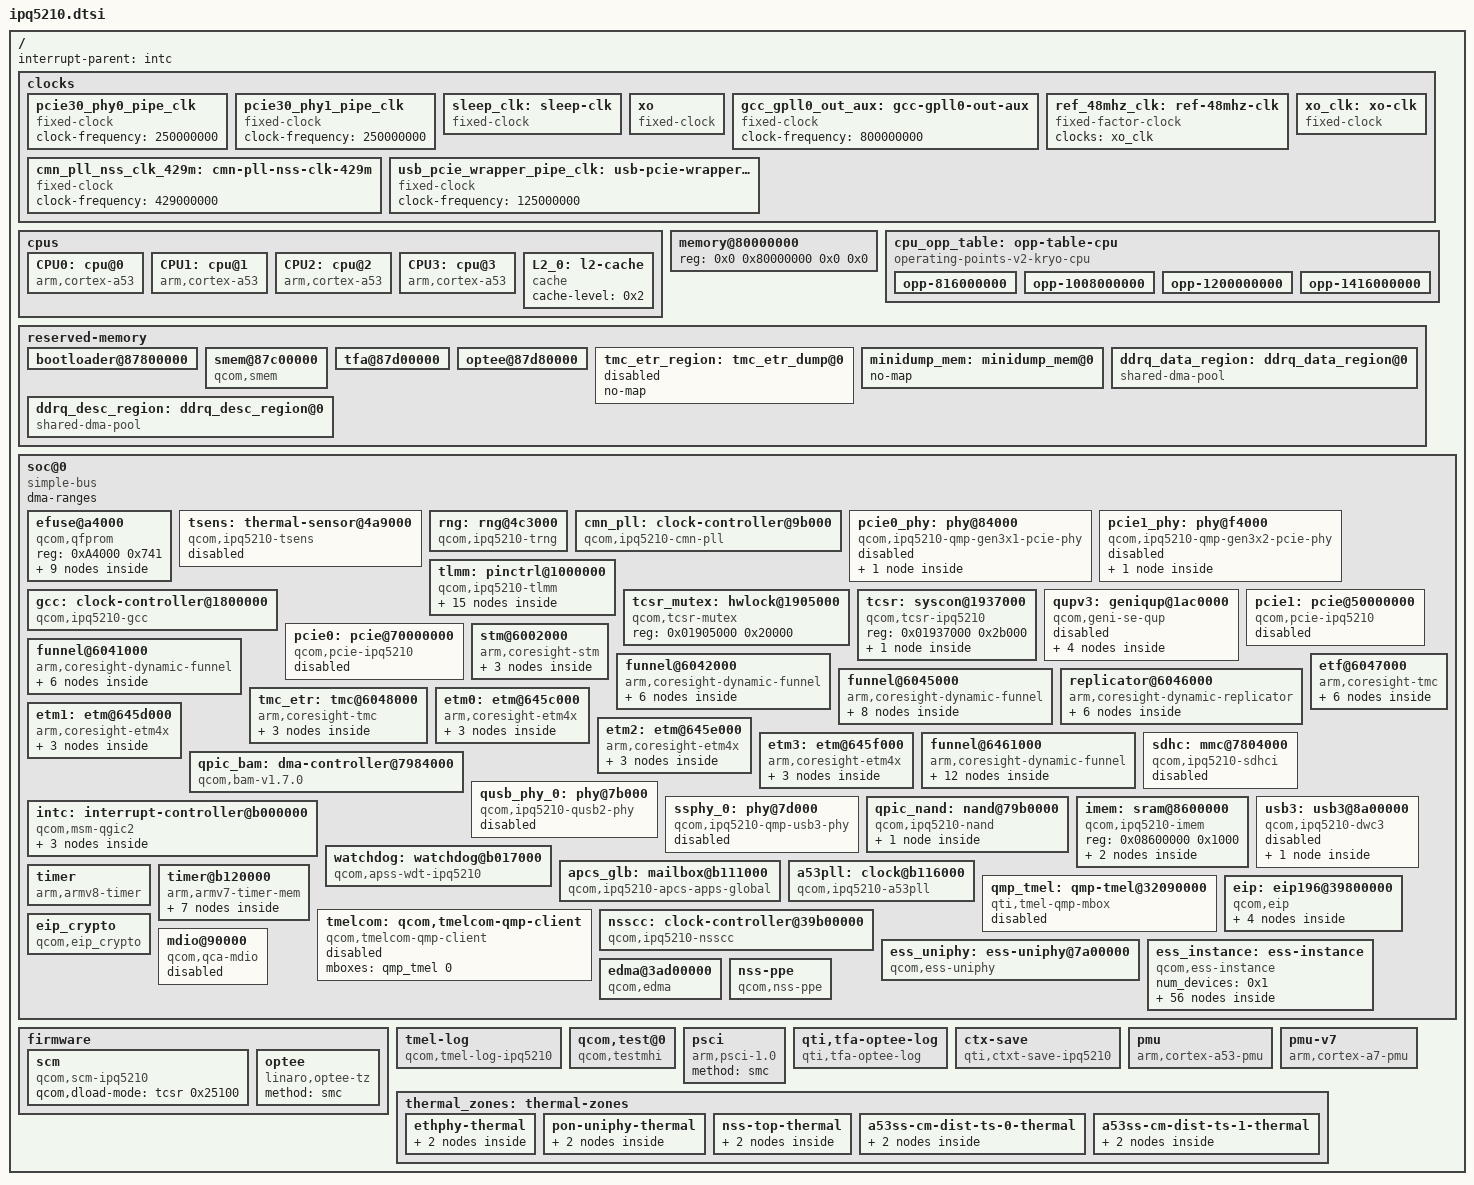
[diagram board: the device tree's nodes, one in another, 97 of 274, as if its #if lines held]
// SPDX-License-Identifier: (GPL-2.0+ OR BSD-3-Clause)
/*
 * IPQ5210 device tree source
 *
 * Copyright (c) 2020-2021 The Linux Foundation. All rights reserved.
 * Copyright (c) Qualcomm Technologies, Inc. and/or its subsidiaries.
 */

#include <dt-bindings/clock/qcom,apss-ipq.h>
#include <dt-bindings/clock/qcom,ipq5210-cmn-pll.h>
#include <dt-bindings/clock/qcom,ipq5210-gcc.h>
#include <dt-bindings/clock/qcom,ipq5210-nsscc.h>
#include <dt-bindings/reset/qcom,ipq5210-gcc.h>
#include <dt-bindings/reset/qcom,ipq5210-nsscc.h>
#include <dt-bindings/interrupt-controller/arm-gic.h>
#include <dt-bindings/gpio/gpio.h>

/ {
	#address-cells = <2>;
	#size-cells = <2>;
	interrupt-parent = <&intc>;

	clocks {
		pcie30_phy0_pipe_clk: pcie30_phy0_pipe_clk {
			compatible = "fixed-clock";
			clock-frequency = <250000000>;
			#clock-cells = <0>;
		};

		pcie30_phy1_pipe_clk: pcie30_phy1_pipe_clk {
			compatible = "fixed-clock";
			clock-frequency = <250000000>;
			#clock-cells = <0>;
		};

		sleep_clk: sleep-clk {
			compatible = "fixed-clock";
			#clock-cells = <0>;
		};

		xo: xo {
			compatible = "fixed-clock";
			#clock-cells = <0>;
		};

		gcc_gpll0_out_aux: gcc-gpll0-out-aux {
			compatible = "fixed-clock";
			clock-frequency = <800000000>;
			#clock-cells = <0>;
		};

		ref_48mhz_clk: ref-48mhz-clk {
			compatible = "fixed-factor-clock";
			clocks = <&xo_clk>;
			#clock-cells = <0>;
		};

		xo_clk: xo-clk {
			compatible = "fixed-clock";
			#clock-cells = <0>;
		};

		cmn_pll_nss_clk_429m: cmn-pll-nss-clk-429m {
			compatible = "fixed-clock";
			clock-frequency = <429000000>;
			#clock-cells = <0>;
		};

		usb_pcie_wrapper_pipe_clk: usb-pcie-wrapper-pipe-clk {
			compatible = "fixed-clock";
			clock-frequency = <125000000>;
			#clock-cells = <0>;
		};
	};

	cpus: cpus {
		#address-cells = <1>;
		#size-cells = <0>;

		CPU0: cpu@0 {
			device_type = "cpu";
			compatible = "arm,cortex-a53";
			reg = <0x0>;
			enable-method = "psci";
			next-level-cache = <&L2_0>;
			clocks = <&apcs_glb APCS_ALIAS0_CORE_CLK>;
			clock-names = "cpu";
			operating-points-v2 = <&cpu_opp_table>;
		};

		CPU1: cpu@1 {
			device_type = "cpu";
			compatible = "arm,cortex-a53";
			enable-method = "psci";
			reg = <0x1>;
			next-level-cache = <&L2_0>;
			clocks = <&apcs_glb APCS_ALIAS0_CORE_CLK>;
			clock-names = "cpu";
			operating-points-v2 = <&cpu_opp_table>;
		};

		CPU2: cpu@2 {
			device_type = "cpu";
			compatible = "arm,cortex-a53";
			enable-method = "psci";
			reg = <0x2>;
			next-level-cache = <&L2_0>;
			clocks = <&apcs_glb APCS_ALIAS0_CORE_CLK>;
			clock-names = "cpu";
			operating-points-v2 = <&cpu_opp_table>;
		};

		CPU3: cpu@3 {
			device_type = "cpu";
			compatible = "arm,cortex-a53";
			enable-method = "psci";
			reg = <0x3>;
			next-level-cache = <&L2_0>;
			clocks = <&apcs_glb APCS_ALIAS0_CORE_CLK>;
			clock-names = "cpu";
			operating-points-v2 = <&cpu_opp_table>;
		};

		L2_0: l2-cache {
			compatible = "cache";
			cache-level = <0x2>;
		};
	};

	memory@80000000 {
		device_type = "memory";
		/* We expect the bootloader to fill in the size */
		reg = <0x0 0x80000000 0x0 0x0 >;
	};

	cpu_opp_table: opp-table-cpu {
		compatible = "operating-points-v2-kryo-cpu";
		opp-shared;
		nvmem-cells = <&apss_cpu_freq>;
		nvmem-cell-names = "cpu_freq";

		/* Listed all supported CPU frequencies and opp-supported-hw
		 * values to select CPU frequencies based on the PLL LValue.
		 * ------------------------------------------------------------
		 * Frequency     1.2GHz   1.4GHz	opp-supported-hw
		 * ------------------------------------------------------------
		 * 816000000       1	      1			0x3
		 * 1008000000	   1	      1			0x3
		 * 1200000000      1	      1			0x3
		 * 1416000000      0	      1			0x1
		 * -----------------------------------------------------------*/

		opp-816000000 {
			opp-hz = /bits/ 64 <816000000>;
			opp-supported-hw = <0x3>;
			opp-microvolt = <850000>;
			clock-latency-ns = <200000>;
		};

		opp-1008000000 {
			opp-hz = /bits/ 64 <1008000000>;
			opp-supported-hw = <0x3>;
			opp-microvolt = <850000>;
			clock-latency-ns = <200000>;
		};

		opp-1200000000 {
			opp-hz = /bits/ 64 <1200000000>;
			opp-supported-hw = <0x3>;
			opp-microvolt = <850000>;
			clock-latency-ns = <200000>;
		};

		opp-1416000000 {
			opp-hz = /bits/ 64 <1416000000>;
			opp-supported-hw = <0x1>;
			opp-microvolt = <1000000>;
			clock-latency-ns = <200000>;
		};
	};

	reserved-memory {
		#address-cells = <2>;
		#size-cells = <2>;
		ranges;

		bootloader@87800000 {
			reg = <0x0 0x87800000 0x0 0x400000>;
			no-map;
		};

		smem@87c00000 {
			compatible = "qcom,smem";
			reg = <0x0 0x87c00000 0x0 0x40000>;
			no-map;

			hwlocks = <&tcsr_mutex 3>;
		};

		tfa@87d00000 {
			reg = <0x0 0x87d00000 0x0 0x80000>;
			no-map;
		};

		optee@87d80000 {
#ifdef __IPQ_MEM_PROFILE_256_MB__
			reg = <0x0 0x87d80000 0x0 0x80000>;
#else
			reg = <0x0 0x87d80000 0x0 0x280000>;
#endif
			no-map;
		};

		tmc_etr_region: tmc_etr_dump@0 {
			no-map;
			status = "disabled";
		};

		minidump_mem: minidump_mem@0 {
			no-map;
		};

		/*
		 * DDRQ data region details
		 */
		ddrq_data_region: ddrq_data_region@0 {
			compatible = "shared-dma-pool";
			no-map;
			size = <0x0 0x00800000>;	/* 8MB */
		};

		/*
		 * DDRQ descriptor memory details
		 */
		ddrq_desc_region: ddrq_desc_region@0 {
			compatible = "shared-dma-pool";
			no-map;
			size = <0x0 0x00080000>;	/* 512KB */
		};
	};

	soc@0 {
		compatible = "simple-bus";
		#address-cells = <1>;
		#size-cells = <1>;
		ranges = <0 0 0 0xffffffff>;
		dma-ranges;

		efuse@a4000 {
			compatible = "qcom,qfprom";
			reg = <0xA4000 0x741>;
			#address-cells = <1>;
			#size-cells = <1>;

			apss_cpu_freq: apss_cpu_freq@28 {
				reg = <0x28 0x1>;
				bits = <0 8>;
			};

			s11: s11@3dd {
				reg = <0x3dd 0x1>;
				bits = <4 4>;
			};

			s12: s12@3de {
				reg = <0x3de 0x1>;
				bits = <0 4>;
			};

			s13: s13@3de {
				reg = <0x3de 0x1>;
				bits = <4 4>;
			};

			s14: s14@3e5 {
				reg = <0x3e5 0x2>;
				bits = <7 4>;
			};

			s15: s15@3e6 {
				reg = <0x3e6 0x1>;
				bits = <3 4>;
			};

			tsens_mode: mode@419 {
				reg = <0x419 0x1>;
				bits = <0 3>;
			};

			tsens_base0: base0@419 {
				reg = <0x419 0x2>;
				bits = <3 10>;
			};

			tsens_base1: base1@41a {
				reg = <0x41a 0x2>;
				bits = <5 10>;
			};
		};

		tsens: thermal-sensor@4a9000 {
			compatible = "qcom,ipq5210-tsens";
			reg = <0x4a9000 0x1000>,
			      <0x4a8000 0x1000>;
			nvmem-cells = <&tsens_mode>, <&tsens_base0>, <&tsens_base1>,
				      <&s11>, <&s12>, <&s13>, <&s14>, <&s15>;
			nvmem-cell-names = "mode", "base0", "base1", "s11",
					   "s12", "s13", "s14", "s15";
			interrupts = <GIC_SPI 52 IRQ_TYPE_EDGE_RISING>;
			interrupt-names = "combined";
			#thermal-sensor-cells = <1>;
			status = "disabled";
		};

		rng: rng@4c3000 {
			compatible = "qcom,ipq5210-trng", "qcom,trng";
			reg = <0x004c3000 0x1000>;
			clocks = <&gcc GCC_QRNG_AHB_CLK>;
			clock-names = "core";
		};

		cmn_pll: clock-controller@9b000 {
			compatible = "qcom,ipq5210-cmn-pll";
			reg = <0x0009b000 0x800>;
			clocks = <&ref_48mhz_clk>,
				 <&gcc GCC_CMN_12GPLL_AHB_CLK>,
				 <&gcc GCC_CMN_12GPLL_SYS_CLK>;
			clock-names = "ref", "ahb", "sys";
			#clock-cells = <1>;
			assigned-clocks = <&cmn_pll IPQ5210_CMN_PLL_CLK>;
			assigned-clock-rates-u64 = /bits/ 64 <12000000000>;
		};

		pcie0_phy: phy@84000 {
			compatible = "qcom,ipq5210-qmp-gen3x1-pcie-phy";
			reg = <0x00084000 0x1bc>; /* Serdes PLL */
			#address-cells = <1>;
			#size-cells = <1>;
			ranges;

			clocks = <&gcc GCC_PCIE0_AUX_CLK>,
				 <&gcc GCC_PCIE0_AHB_CLK>,
				 <&gcc GCC_SNOC_PCIE0_AXI_M_CLK>,
				 <&gcc GCC_CNOC_PCIE0_1LANE_S_CLK>;
			clock-names = "aux", "cfg_ahb", "snoc_lane", "anoc_lane";

			assigned-clocks = <&gcc GCC_PCIE0_AUX_CLK>,
					  <&gcc GCC_PCIE0_AHB_CLK>,
					  <&gcc GCC_SNOC_PCIE0_AXI_M_CLK>,
					  <&gcc GCC_CNOC_PCIE0_1LANE_S_CLK>;
			assigned-clock-rates = <20000000>,
					       <100000000>,
					       <200000000>,
					       <240000000>;

			resets = <&gcc GCC_PCIE0_PHY_BCR>,
				 <&gcc GCC_PCIE0PHY_PHY_BCR>;
			reset-names = "phy", "common";

			status = "disabled";

			pcie0_lanes: phy@84200 {
				reg = <0x00084200 0x16c>, /* Serdes Tx0 */
				      <0x00084400 0x200>, /* Serdes Rx0 */
				      <0x00084800 0x1f0>, /* PCS: Lane0, COM, PCIE */
				      <0x00084c00 0x0f4>; /* pcs_misc */

				#phy-cells = <0>;

				clocks = <&gcc GCC_PCIE0_PIPE_CLK>;
				clock-names = "pipe0";
				clock-output-names = "gcc_pcie0_pipe_clk_src";
				#clock-cells = <0>;
			};
		};

		pcie1_phy: phy@f4000 {
			compatible = "qcom,ipq5210-qmp-gen3x2-pcie-phy",
				     "qcom,ipq9574-qmp-gen3x2-pcie-phy";
			reg = <0x000f4000 0x1bc>; /* Serdes PLL */
			#address-cells = <1>;
			#size-cells = <1>;
			ranges;

			clocks = <&gcc GCC_PCIE1_AUX_CLK>,
				 <&gcc GCC_PCIE1_AHB_CLK>,
				 <&gcc GCC_SNOC_PCIE1_AXI_M_CLK>,
				 <&gcc GCC_CNOC_PCIE1_2LANE_S_CLK>;
			clock-names = "aux", "cfg_ahb", "snoc_lane", "anoc_lane";

			assigned-clocks = <&gcc GCC_PCIE1_AUX_CLK>,
					  <&gcc GCC_PCIE1_AHB_CLK>,
					  <&gcc GCC_SNOC_PCIE1_AXI_M_CLK>,
					  <&gcc GCC_CNOC_PCIE1_2LANE_S_CLK>;
			assigned-clock-rates = <20000000>,
					       <100000000>,
					       <266666666>,
					       <240000000>;

			resets = <&gcc GCC_PCIE1_PHY_BCR>,
				 <&gcc GCC_PCIE1PHY_PHY_BCR>;
			reset-names = "phy", "common";

			status = "disabled";

			pcie1_lanes: phy@f4200 {
				reg = <0x000f4200 0x16c>, /* Serdes Tx0 */
				      <0x000f4400 0x200>, /* Serdes Rx0 */
				      <0x000f5000 0x1f0>, /* PCS: Lane0, COM, PCIE */
				      <0x000f4600 0x16c>, /* Serdes Tx1 */
				      <0x000f4800 0x200>, /* Serdes Rx1 */
				      <0x000f5400 0x0f8>; /* pcs_misc */

				#phy-cells = <0>;

				clocks = <&gcc GCC_PCIE1_PIPE_CLK>;
				clock-names = "pipe0";
				clock-output-names = "gcc_pcie1_pipe_clk_src";
				#clock-cells = <0>;
			};
		};

		tlmm: pinctrl@1000000 {
			compatible = "qcom,ipq5210-tlmm";
			reg = <0x1000000 0x300000>;
			interrupts = <GIC_SPI 31 IRQ_TYPE_LEVEL_HIGH>;
			gpio-controller;
			#gpio-cells = <2>;
			gpio-ranges = <&tlmm 0 0 54>;
			interrupt-controller;
			#interrupt-cells = <2>;

			mdio_pins: mdio-state {
				mux_0 {
					pins = "gpio26";
					function = "mdc_mst";
					drive-strength = <6>;
					bias-pull-down;
				};

				mux_1 {
					pins = "gpio27";
					function = "mdio_mst";
					drive-strength = <6>;
					bias-pull-down;
				};
			};

                        pon_cmn_pins: pon-cmn-pins {

				pon_active_led {
					pins = "gpio11";
					function = "pon_active_led";
					drive-strength = <6>;
					bias-pull-down;
				};

				pon_tx_pwr_on {
					pins = "gpio15";
					function = "pon_tx";
					drive-strength = <6>;
					bias-pull-down;
				};

				pon_rx_pwr_on {
					pins = "gpio48";
					function = "pon_rx";
					drive-strength = <6>;
					bias-pull-down;
				};
			};

			xgspon_pins: xgspon-pins {

				pon_tx_burst {
					pins = "gpio14";
					function = "pon_tx_burst";
					drive-strength = <6>;
					bias-disable;
				};

				pon_tx_fault {
					pins = "gpio17";
					function = "pon_tx_fault";
					drive-strength = <6>;
					bias-pull-down;
				};

				pon_tx_sd {
					pins = "gpio16";
					function = "pon_tx_sd";
					drive-strength = <6>;
					bias-pull-down;
				};

				pon_rx_los {
					pins = "gpio10";
					function = "pon_rx_los";
					drive-strength = <6>;
					bias-pull-up;
				};

				pon_tx_dis {
					pins = "gpio12";
					function = "pon_tx_dis";
					drive-strength = <6>;
					bias-pull-down;
				};
			};

			pps_state: pps-state {
				pps-pins {
					pins = "gpio18";
					function = "pps";
					drive-strength = <8>;
					bias-pull-down;
				};
			};
		};

		gcc: clock-controller@1800000 {
			compatible = "qcom,ipq5210-gcc";
			reg = <0x01800000 0x40000>;
			clocks = <&xo>,
				 <&sleep_clk>,
				 <&pcie30_phy0_pipe_clk>,
				 <&pcie30_phy1_pipe_clk>,
				 <&usb_pcie_wrapper_pipe_clk>,
				 <&cmn_pll_nss_clk_429m>;
			#clock-cells = <1>;
			#reset-cells = <1>;
			#power-domain-cells = <1>;
		};

		tcsr_mutex: hwlock@1905000 {
			compatible = "qcom,tcsr-mutex";
			reg = <0x01905000 0x20000>;
			#hwlock-cells = <1>;
		};

		tcsr: syscon@1937000 {
			compatible = "qcom,tcsr-ipq5210", "syscon", "simple-mfd";
			reg = <0x01937000 0x2b000>;
			#address-cells = <1>;
			#size-cells = <1>;
			ranges = <0x0 0x01937000 0x2b000>;

			pwm: pwm@a010 {
				compatible = "qcom,ipq9574-pwm";
				reg = <0xa010 0x20>;
				clocks = <&gcc GCC_ADSS_PWM_CLK>;
				assigned-clocks = <&gcc GCC_ADSS_PWM_CLK>;
				assigned-clock-rates = <100000000>;
				#pwm-cells = <2>;
				status = "disabled";
			};
		};

		qupv3: geniqup@1ac0000 {
			compatible = "qcom,geni-se-qup";
			reg = <0x01ac0000 0x2000>;
			clocks = <&gcc GCC_QUPV3_AHB_MST_CLK>,
				 <&gcc GCC_QUPV3_AHB_SLV_CLK>;
			clock-names = "m-ahb", "s-ahb";
			ranges;
			#address-cells = <1>;
			#size-cells = <1>;

			status = "disabled";

			spi0: spi@1a80000 {
				compatible = "qcom,geni-spi";
				reg = <0x1a80000 0x4000>;
				clocks = <&gcc GCC_QUPV3_WRAP_SE0_CLK>;
				clock-names = "se";
				interrupts = <GIC_SPI 138 IRQ_TYPE_LEVEL_HIGH>;
				assigned-clocks = <&gcc GCC_QUPV3_WRAP_SE0_CLK>;
				assigned-clock-rates = <50000000>;
				status = "disabled";
			};

			uart1: serial@1a84000 {
				compatible = "qcom,geni-debug-uart";
				reg = <0x1a84000 0x4000>;
				clocks = <&gcc GCC_QUPV3_WRAP_SE1_CLK>;
				clock-names = "se";
				interrupts = <GIC_SPI 139 IRQ_TYPE_LEVEL_HIGH>;
				status = "disabled";
			};

			i2c0: i2c@1a88000 {
				compatible = "qcom,geni-i2c";
				reg = <0x1a88000 0x4000>;
				clocks = <&gcc GCC_QUPV3_WRAP_SE2_CLK>;
				clock-names = "se";
				clock-frequency = <400000>;
				interrupts = <GIC_SPI 140 IRQ_TYPE_LEVEL_HIGH>;
				assigned-clocks = <&gcc GCC_QUPV3_WRAP_SE2_CLK>;
				assigned-clock-rates = <32000000>;
				status = "disabled";
			};

			i2c1: i2c@1a8c000 {
				compatible = "qcom,geni-i2c";
				reg = <0x1a8c000 0x4000>;
				clocks = <&gcc GCC_QUPV3_WRAP_SE3_CLK>;
				clock-names = "se";
				clock-frequency = <400000>;
				interrupts = <GIC_SPI 141 IRQ_TYPE_LEVEL_HIGH>;
				assigned-clocks = <&gcc GCC_QUPV3_WRAP_SE3_CLK>;
				assigned-clock-rates = <32000000>;
				status = "disabled";
			};
		};

		pcie1: pcie@50000000 {
			compatible = "qcom,pcie-ipq5210";
			reg =  <0x50000000 0xf1d>,
			       <0x50000f20 0xa8>,
			       <0x50001000 0x1000>,
			       <0xf0000 0x3000>,
			       <0x50100000 0x1000>;
			reg-names = "dbi", "elbi", "atu", "parf", "config";
			device_type = "pci";
			linux,pci-domain = <1>;
			bus-range = <0x00 0xff>;
			num-lanes = <2>;
			#address-cells = <3>;
			#size-cells = <2>;
			qcom,aspm-enabled;
			axi-halt-val = <0x1e>; /* increase halt window size to 1GB */

			ranges = <0x81000000 0 0x50200000 0x50200000 0 0x00100000>,   /* downstream I/O */
				 <0x82000000 0 0x50300000 0x50300000 0 0x0fd00000>; /* non-prefetchable memory */

			#interrupt-cells = <1>;
			interrupt-map-mask = <0 0 0 0x7>;
			interrupt-map = <0 0 0 1 &intc 0 200 IRQ_TYPE_LEVEL_HIGH>, /* int_a */
					<0 0 0 2 &intc 0 201 IRQ_TYPE_LEVEL_HIGH>, /* int_b */
					<0 0 0 3 &intc 0 202 IRQ_TYPE_LEVEL_HIGH>, /* int_c */
					<0 0 0 4 &intc 0 203 IRQ_TYPE_LEVEL_HIGH>; /* int_d */

			interrupts = <GIC_SPI 199 IRQ_TYPE_LEVEL_HIGH>;
			interrupt-names = "global_irq";

			clocks = <&gcc GCC_PCIE1_AXI_M_CLK>,
				 <&gcc GCC_PCIE1_AXI_S_CLK>,
				 <&gcc GCC_PCIE1_AHB_CLK>,
				 <&gcc GCC_PCIE1_AUX_CLK>,
				 <&gcc GCC_PCIE1_AXI_S_BRIDGE_CLK>,
				 <&gcc GCC_PCIE1_RCHNG_CLK>;

			clock-names = "axi_m",
				      "axi_s",
				      "ahb",
				      "aux",
				      "axi_bridge",
				      "rchng";

			assigned-clocks = <&gcc GCC_PCIE1_AHB_CLK>,
					<&gcc GCC_PCIE1_AUX_CLK>,
					<&gcc GCC_PCIE1_AXI_M_CLK>,
					<&gcc GCC_PCIE1_AXI_S_BRIDGE_CLK>,
					<&gcc GCC_PCIE1_AXI_S_CLK>,
					<&gcc GCC_PCIE1_RCHNG_CLK>;

			assigned-clock-rates = <100000000>,
						<20000000>,
						<266666666>,
						<240000000>,
						<240000000>,
						<100000000>;

			resets = <&gcc GCC_PCIE1_PIPE_ARES>,
				 <&gcc GCC_PCIE1_CORE_STICKY_RESET>,
				 <&gcc GCC_PCIE1_AXI_M_ARES>,
				 <&gcc GCC_PCIE1_AXI_S_ARES>,
				 <&gcc GCC_PCIE1_AXI_M_STICKY_RESET>,
				 <&gcc GCC_PCIE1_AXI_S_STICKY_RESET>,
				 <&gcc GCC_PCIE1_AHB_ARES>,
				 <&gcc GCC_PCIE1_AUX_ARES>;

			reset-names = "pipe",
				      "sticky",
				      "axi_m",
				      "axi_s",
				      "axi_m_sticky",
				      "axi_s_sticky",
				      "ahb",
				      "aux";

			msi-parent = <&v2m0>;

			phys = <&pcie1_lanes>;
			phy-names = "pciephy";

			status = "disabled";
		};

		pcie0: pcie@70000000 {
			compatible = "qcom,pcie-ipq5210";
			reg =  <0x70000000 0xf1d>,
			       <0x70000f20 0xa8>,
			       <0x70001000 0x1000>,
			       <0x80000 0x3000>,
			       <0x70100000 0x1000>;
			reg-names = "dbi", "elbi", "atu", "parf", "config";
			device_type = "pci";
			linux,pci-domain = <0>;
			bus-range = <0x00 0xff>;
			num-lanes = <1>;
			#address-cells = <3>;
			#size-cells = <2>;
			qcom,aspm-enabled;
			axi-halt-val = <0x1e>; /* increase halt window size to 1GB */

			ranges = <0x81000000 0 0x70200000 0x70200000 0 0x00100000>,   /* downstream I/O */
				 <0x82000000 0 0x70300000 0x70300000 0 0x0fd00000>; /* non-prefetchable memory */

			#interrupt-cells = <1>;
			interrupt-map-mask = <0 0 0 0x7>;
			interrupt-map = <0 0 0 1 &intc 0 185 IRQ_TYPE_LEVEL_HIGH>, /* int_a */
					<0 0 0 2 &intc 0 186 IRQ_TYPE_LEVEL_HIGH>, /* int_b */
					<0 0 0 3 &intc 0 187 IRQ_TYPE_LEVEL_HIGH>, /* int_c */
					<0 0 0 4 &intc 0 188 IRQ_TYPE_LEVEL_HIGH>; /* int_d */

			interrupts = <GIC_SPI 184 IRQ_TYPE_LEVEL_HIGH>;
			interrupt-names = "global_irq";

			clocks = <&gcc GCC_PCIE0_AXI_M_CLK>,
				 <&gcc GCC_PCIE0_AXI_S_CLK>,
				 <&gcc GCC_PCIE0_AHB_CLK>,
				 <&gcc GCC_PCIE0_AUX_CLK>,
				 <&gcc GCC_PCIE0_AXI_S_BRIDGE_CLK>,
				 <&gcc GCC_PCIE0_RCHNG_CLK>;

			clock-names = "axi_m",
				      "axi_s",
				      "ahb",
				      "aux",
				      "axi_bridge",
				      "rchng";

			assigned-clocks = <&gcc GCC_PCIE0_AHB_CLK>,
					<&gcc GCC_PCIE0_AUX_CLK>,
					<&gcc GCC_PCIE0_AXI_M_CLK>,
					<&gcc GCC_PCIE0_AXI_S_BRIDGE_CLK>,
					<&gcc GCC_PCIE0_AXI_S_CLK>,
					<&gcc GCC_PCIE0_RCHNG_CLK>;

			assigned-clock-rates = <100000000>,
						<20000000>,
						<240000000>,
						<240000000>,
						<240000000>,
						<100000000>;

			resets = <&gcc GCC_PCIE0_PIPE_ARES>,
				 <&gcc GCC_PCIE0_CORE_STICKY_RESET>,
				 <&gcc GCC_PCIE0_AXI_M_ARES>,
				 <&gcc GCC_PCIE0_AXI_S_ARES>,
				 <&gcc GCC_PCIE0_AXI_M_STICKY_RESET>,
				 <&gcc GCC_PCIE0_AXI_S_STICKY_RESET>,
				 <&gcc GCC_PCIE0_AHB_ARES>,
				 <&gcc GCC_PCIE0_AUX_ARES>;

			reset-names = "pipe",
				      "sticky",
				      "axi_m",
				      "axi_s",
				      "axi_m_sticky",
				      "axi_s_sticky",
				      "ahb",
				      "aux";

			msi-parent = <&v2m0>;

			phys = <&pcie0_lanes>;
			phy-names = "pciephy";

			status = "disabled";
		};

		stm@6002000 {
			compatible = "arm,coresight-stm", "arm,primecell";
			reg = <0x06002000 0x1000>,
				<0x09000000 0x1000000>;
			reg-names = "stm-base", "stm-stimulus-base";
			coresight-name = "coresight-stm";
			clocks = <&gcc GCC_QDSS_DAP_CLK>,
				 <&gcc GCC_QDSS_AT_CLK>;
			clock-names = "apb_pclk", "atclk";

			out-ports {
				port {
					stm_out: endpoint {
						remote-endpoint = <&funnel0_in7>;
					};
				};
			};
		};

		funnel@6041000 {
			compatible = "arm,coresight-dynamic-funnel", "arm,primecell";
			reg = <0x06041000 0x1000>;
			reg-names = "funnel-base";
			coresight-name = "coresight-funnel-in0";
			clocks = <&gcc GCC_QDSS_DAP_CLK>,
				 <&gcc GCC_QDSS_AT_CLK>;
			clock-names = "apb_pclk", "atclk";

			in-ports {
				#address-cells = <1>;
				#size-cells = <0>;

				/*
				 * Port 0 - TME
				 * Port 2 - SNOC
				 * Port 3 - NSS
				 * Port 4 - CNOC
				 * Port 6 - TPDA QDSS
				 * Port 7 - STM_SS
				 */

				port@7 {
					reg = <7>;
					funnel0_in7: endpoint {
						remote-endpoint = <&stm_out>;
					};
				};
			};

			out-ports {
				port {
					funnel0_out: endpoint {
						remote-endpoint = <&merge_funnel_in0>;
					};
				};
			};
		};

		funnel@6042000 {
			compatible = "arm,coresight-dynamic-funnel", "arm,primecell";
			reg = <0x06042000 0x1000>;
			reg-names = "funnel-base";
			coresight-name = "coresight-funnel-in1";
			clocks = <&gcc GCC_QDSS_DAP_CLK>,
				 <&gcc GCC_QDSS_AT_CLK>;
			clock-names = "apb_pclk", "atclk";

			in-ports {
				#address-cells = <1>;
				#size-cells = <0>;

				/*
				 * Port 1 - MEMNOC
				 * Port 3 - TPDA QDSS
				 * Port 4 - APSS
				 */

				port@4 {
					reg = <4>;
					funnel1_in2: endpoint {
						remote-endpoint = <&apss_funnel_out>;
					};
				};
			};

			out-ports {
				port {
					funnel1_out: endpoint {
						remote-endpoint = <&merge_funnel_in1>;
					};
				};
			};
		};

		funnel@6045000 {
			compatible = "arm,coresight-dynamic-funnel", "arm,primecell";
			reg = <0x06045000 0x1000>;
			reg-names = "funnel-base";
			coresight-name = "coresight-funnel-merge";
			clocks = <&gcc GCC_QDSS_DAP_CLK>,
				 <&gcc GCC_QDSS_AT_CLK>;
			clock-names = "apb_pclk", "atclk";

			out-ports {
				port {
					merge_funnel_out: endpoint {
						remote-endpoint = <&etf_in>;
					};
				};
			};

			in-ports {
				#address-cells = <1>;
				#size-cells = <0>;

				port@0 {
					reg = <0>;
					merge_funnel_in0: endpoint {
						remote-endpoint = <&funnel0_out>;
					};
				};

				port@1 {
					reg = <1>;
					merge_funnel_in1: endpoint {
						remote-endpoint = <&funnel1_out>;
					};
				};
			};

		};

		replicator@6046000 {
			compatible = "arm,coresight-dynamic-replicator", "arm,primecell";
			reg = <0x06046000 0x1000>;
			reg-names = "replicator-base";
			coresight-name = "coresight-replicator";
			clocks = <&gcc GCC_QDSS_DAP_CLK>,
				 <&gcc GCC_QDSS_AT_CLK>;
			clock-names = "apb_pclk", "atclk";

			out-ports {
				#address-cells = <1>;
				#size-cells = <0>;

				port@0 {
					reg = <0>;
					etr_replicator_out0: endpoint {
						remote-endpoint = <&etr_in>;
					};
				};
			};

			in-ports {
				port {
					etr_replicator_in0: endpoint {
						remote-endpoint = <&etf_out>;
					};
				};
			};
		};

		etf@6047000 {
			compatible = "arm,coresight-tmc", "arm,primecell";
			reg = <0x06047000 0x1000>;
			reg-names = "tmc-base";
			coresight-name = "coresight-tmc-etf";
			arm,default-sink;
			clocks = <&gcc GCC_QDSS_DAP_CLK>;
			clock-names = "apb_pclk";

			out-ports {
				port {
					etf_out: endpoint {
						remote-endpoint = <&etr_replicator_in0>;
					};
				};
			};

			in-ports {
				port {
					etf_in: endpoint {
						remote-endpoint = <&merge_funnel_out>;
					};
				};
			};
		};

		tmc_etr: tmc@6048000 {
			compatible = "arm,coresight-tmc", "arm,primecell";
			reg = <0x06048000 0x1000>;
			reg-names = "tmc-base";
			interrupts = <GIC_SPI 155 IRQ_TYPE_EDGE_RISING>;
			interrupt-names = "byte-cntr-irq";
			arm,buffer-size = <0x100000>;
			arm,scatter-gather;
			memory-region = <&tmc_etr_region>;
			coresight-name = "coresight-tmc-etr";
			clocks = <&gcc GCC_QDSS_DAP_CLK>;
			clock-names = "apb_pclk";

			in-ports {
				port {
					etr_in: endpoint {
						remote-endpoint = <&etr_replicator_out0>;
					};
				};
			};
		};

		etm0: etm@645c000 {
			compatible = "arm,coresight-etm4x", "arm,primecell";
			reg = <0x0645c000 0x1000>;
			coresight-name = "coresight-etm0";
			cpu = <&CPU0>;
			clocks = <&gcc GCC_QDSS_DAP_CLK>;
			clock-names = "apb_pclk";

			out-ports {
				port {
					etm0_out: endpoint {
						remote-endpoint = <&apss_funnel_in0>;
					};
				};
			};
		};

		etm1: etm@645d000 {
			compatible = "arm,coresight-etm4x", "arm,primecell";
			reg = <0x0645d000 0x1000>;
			coresight-name = "coresight-etm1";
			cpu = <&CPU1>;
			clocks = <&gcc GCC_QDSS_DAP_CLK>;
			clock-names = "apb_pclk";

			out-ports {
				port {
					etm1_out: endpoint {
						remote-endpoint = <&apss_funnel_in1>;
					};
				};
			};
		};

		etm2: etm@645e000 {
			compatible = "arm,coresight-etm4x", "arm,primecell";
			reg = <0x0645e000 0x1000>;
			coresight-name = "coresight-etm2";
			cpu = <&CPU2>;
			clocks = <&gcc GCC_QDSS_DAP_CLK>;
			clock-names = "apb_pclk";

			out-ports {
				port {
					etm2_out: endpoint {
						remote-endpoint = <&apss_funnel_in2>;
					};
				};
			};
		};

		etm3: etm@645f000 {
			compatible = "arm,coresight-etm4x", "arm,primecell";
			reg = <0x0645f000 0x1000>;
			coresight-name = "coresight-etm3";
			cpu = <&CPU3>;
			clocks = <&gcc GCC_QDSS_DAP_CLK>;
			clock-names = "apb_pclk";

			out-ports {
				port {
					etm3_out: endpoint {
						remote-endpoint = <&apss_funnel_in3>;
					};
				};
			};
		};

		funnel@6461000 {
			compatible = "arm,coresight-dynamic-funnel", "arm,primecell";
			reg = <0x06461000 0x1000>;
			reg-names = "funnel-base";
			coresight-name = "coresight-funnel-apss";
			clocks = <&gcc GCC_QDSS_DAP_CLK>,
				 <&gcc GCC_QDSS_AT_CLK>;
			clock-names = "apb_pclk", "atclk";

			out-ports {
				port {
					apss_funnel_out: endpoint {
						remote-endpoint = <&funnel1_in2>;
					};
				};
			};

			in-ports {
				#address-cells = <1>;
				#size-cells = <0>;

				port@0 {
					reg = <0>;
					apss_funnel_in0: endpoint {
						remote-endpoint = <&etm0_out>;
					};
				};

				port@1 {
					reg = <1>;
					apss_funnel_in1: endpoint {
						remote-endpoint = <&etm1_out>;
					};
				};

				port@2 {
					reg = <2>;
					apss_funnel_in2: endpoint {
						remote-endpoint = <&etm2_out>;
					};
				};

				port@3 {
					reg = <3>;
					apss_funnel_in3: endpoint {
						remote-endpoint = <&etm3_out>;
					};
				};
			};
		};

		sdhc: mmc@7804000 {
			compatible = "qcom,ipq5210-sdhci", "qcom,sdhci-msm-v5";
			reg = <0x07804000 0x1000>, <0x07805000 0x1000>;
			reg-names = "hc", "cqhci";

			interrupts = <GIC_SPI 63 IRQ_TYPE_LEVEL_HIGH>,
				     <GIC_SPI 66 IRQ_TYPE_LEVEL_HIGH>;
			interrupt-names = "hc_irq", "pwr_irq";

			clocks = <&gcc GCC_SDCC1_AHB_CLK>,
				 <&gcc GCC_SDCC1_APPS_CLK>,
				 <&xo>;
			clock-names = "iface", "core", "xo";

			status = "disabled";
		};

		qpic_bam: dma-controller@7984000 {
			compatible = "qcom,bam-v1.7.0";
			reg = <0x7984000 0x1c000>;
			interrupts = <GIC_SPI 56 IRQ_TYPE_LEVEL_HIGH>;
			clocks = <&gcc GCC_QPIC_AHB_CLK>;
			clock-names = "bam_clk";
			#dma-cells = <1>;
			qcom,ee = <0>;
			qcom,bam-lite;
			status = "okay";
		};

		qusb_phy_0: phy@7b000 {
			compatible = "qcom,ipq5210-qusb2-phy";
			reg = <0x07b000 0x180>;
			#phy-cells = <0>;

			clocks = <&gcc GCC_USB0_PHY_CFG_AHB_CLK>,
				<&xo>;
			clock-names = "cfg_ahb", "ref";

			resets = <&gcc GCC_QUSB2_0_PHY_BCR>;
			status = "disabled";
		};

		ssphy_0: phy@7d000 {
			compatible = "qcom,ipq5210-qmp-usb3-phy";
			reg = <0x0007d000 0xa00>;
			#phy-cells = <0>;

			clocks = <&gcc GCC_USB0_AUX_CLK>,
				 <&xo>,
				 <&gcc GCC_USB0_PHY_CFG_AHB_CLK>,
				 <&gcc GCC_USB0_PIPE_CLK>;
			clock-names = "aux",
				      "ref",
				      "cfg_ahb",
				      "pipe";

			resets = <&gcc GCC_USB0_PHY_BCR>,
				 <&gcc GCC_USB3PHY_0_PHY_BCR>;
			reset-names = "phy",
				      "phy_phy";

			#clock-cells = <0>;
			clock-output-names = "usb0_pipe_clk";

			status = "disabled";
		};

		qpic_nand: nand@79b0000 {
			compatible = "qcom,ipq5210-nand";
			reg = <0x79b0000 0x10000>;
			#address-cells = <1>;
			#size-cells = <0>;
			clocks = <&gcc GCC_QPIC_CLK>,
				 <&gcc GCC_QPIC_AHB_CLK>,
				 <&gcc GCC_QPIC_IO_MACRO_CLK>;
			clock-names = "core", "aon", "io_macro";

			dmas = <&qpic_bam 0>,
			       <&qpic_bam 1>,
			       <&qpic_bam 2>,
			       <&qpic_bam 3>;
			dma-names = "tx", "rx", "cmd", "sts";

			qcom,io_macro_max_clk = <320000000>;
			qcom,io_macro_clk_rates = <24000000 100000000 200000000 \
						   320000000>;

			status = "okay";

			nandcs@0 {
				reg = <0>;
				#address-cells = <1>;
				#size-cells = <1>;

				nand-ecc-strength = <8>;
				nand-ecc-step-size = <512>;
				nand-bus-width = <8>;
			};
		};

		imem: sram@8600000 {
			compatible = "qcom,ipq5210-imem", "syscon", "simple-mfd";
			reg = <0x08600000 0x1000>;
			ranges = <0 0x08600000 0x1000>;

			#address-cells = <1>;
			#size-cells = <1>;

			/*
			 * First 4 bytes contains the Diag buffer address
			 * Second 4 bytes contains the Diag buffer size
			 */
			tfa_diag_buf: tfa-diag-buf@720 {
				reg = <0x720 8>;
			};

			/*
			 * First 4 bytes contains the Diag buffer address
			 * Second 4 bytes contains the Diag buffer size
			 */
			optee_diag_buf: optee-diag-buf@730 {
				reg = <0x730 8>;
			};
		};

		usb3: usb3@8a00000 {
			compatible = "qcom,ipq5210-dwc3", "qcom,dwc3";
			reg = <0x8af8800 0x400>,
			      <0x8b80000 0x4000>;
			#address-cells = <1>;
			#size-cells = <1>;
			ranges;

			clocks = <&gcc GCC_USB0_MASTER_CLK>,
				<&gcc GCC_USB0_SLEEP_CLK>,
				<&gcc GCC_USB0_MOCK_UTMI_CLK>,
				<&gcc GCC_USB0_PHY_CFG_AHB_CLK>,
				<&gcc GCC_USB0_AUX_CLK>,
				<&gcc GCC_USB0_PIPE_CLK>,
				<&gcc GCC_CNOC_USB_CLK>;

			clock-names = "master",
				"sleep",
				"mock_utmi",
				"cfg_ahb_clk",
				"aux_clk",
				"pipe_clk",
				"cnoc_usb_clk";

			assigned-clocks = <&gcc GCC_USB0_MASTER_CLK>,
					  <&gcc GCC_USB0_MOCK_UTMI_CLK>;
			assigned-clock-rates = <200000000>,
					       <24000000>;

			resets = <&gcc GCC_USB_BCR>;
			status = "disabled";

			dwc_0: dwc3@8a00000 {
				compatible = "snps,dwc3";
				reg = <0x8a00000 0xcd00>;
				clocks = <&gcc GCC_USB0_MOCK_UTMI_CLK>;
				clock-names = "ref";
				interrupts = <GIC_SPI 161 IRQ_TYPE_LEVEL_HIGH>;
				phys = <&qusb_phy_0>, <&ssphy_0>;
				phy-names = "usb2-phy", "usb3-phy";
				tx-fifo-resize;
				snps,is-utmi-l1-suspend;
				snps,hird-threshold = /bits/ 8 <0x0>;
				snps,dis_u2_susphy_quirk;
				snps,dis_u3_susphy_quirk;
				dr_mode = "host";
			};
		};

		intc: interrupt-controller@b000000 {
			compatible = "qcom,msm-qgic2";
			interrupt-controller;
			#interrupt-cells = <3>;
			reg = <0xb000000 0x1000>,  /*GICD*/
				<0xb002000 0x1000>,  /*GICC*/
				<0xb001000 0x1000>,  /*GICH*/
				<0xb004000 0x1000>;  /*GICV*/
			interrupts = <GIC_PPI 9 IRQ_TYPE_LEVEL_HIGH>;
			#address-cells = <1>;
			#size-cells = <1>;
			ranges = <0 0x0b00c000 0x3000>;

			v2m0: v2m@0 {
				compatible = "arm,gic-v2m-frame";
				reg = <0x00000000 0xffd>;
				msi-controller;
			};

			v2m1: v2m@1000 {
				compatible = "arm,gic-v2m-frame";
				reg = <0x00001000 0xffd>;
				msi-controller;
			};

			v2m2: v2m@2000 {
				compatible = "arm,gic-v2m-frame";
				reg = <0x00002000 0xffd>;
				msi-controller;
			};
		};

		watchdog: watchdog@b017000 {
			compatible = "qcom,apss-wdt-ipq5210", "qcom,kpss-wdt";
			reg = <0x0b017000 0x1000>;
			interrupts = <GIC_SPI 277 IRQ_TYPE_EDGE_RISING>;
			clocks = <&sleep_clk>;
			timeout-sec = <30>;
		};

		apcs_glb: mailbox@b111000 {
			compatible = "qcom,ipq5210-apcs-apps-global",
				     "qcom,ipq6018-apcs-apps-global";
			reg = <0x0b111000 0x1000>;
			#clock-cells = <1>;
			clocks = <&a53pll>, <&xo>, <&gcc GPLL0>;
			clock-names = "pll", "xo", "gpll0";
			#mbox-cells = <1>;
		};

		a53pll: clock@b116000 {
			compatible = "qcom,ipq5210-a53pll";
			reg = <0x0b116000 0x40>;
			#clock-cells = <0>;
			clocks = <&xo>;
			clock-names = "xo";
		};

		timer {
			compatible = "arm,armv8-timer";
			interrupts = <GIC_PPI 2 (GIC_CPU_MASK_SIMPLE(4) | IRQ_TYPE_LEVEL_LOW)>,
				<GIC_PPI 3 (GIC_CPU_MASK_SIMPLE(4) | IRQ_TYPE_LEVEL_LOW)>,
				<GIC_PPI 4 (GIC_CPU_MASK_SIMPLE(4) | IRQ_TYPE_LEVEL_LOW)>,
				<GIC_PPI 1 (GIC_CPU_MASK_SIMPLE(4) | IRQ_TYPE_LEVEL_LOW)>;
			clock-frequency = <24000000>;
		};

		timer@b120000 {
			#address-cells = <1>;
			#size-cells = <1>;
			ranges;
			compatible = "arm,armv7-timer-mem";
			reg = <0xb120000 0x1000>;
			clock-frequency = <24000000>;

			frame@b121000 {
				frame-number = <0>;
				interrupts = <GIC_SPI 8 IRQ_TYPE_LEVEL_HIGH>,
					     <GIC_SPI 7 IRQ_TYPE_LEVEL_HIGH>;
				reg = <0xb121000 0x1000>,
				      <0xb122000 0x1000>;
			};

			frame@b123000 {
				frame-number = <1>;
				interrupts = <GIC_SPI 9 IRQ_TYPE_LEVEL_HIGH>;
				reg = <0xb123000 0x1000>;
				status = "disabled";
			};

			frame@b124000 {
				frame-number = <2>;
				interrupts = <GIC_SPI 10 IRQ_TYPE_LEVEL_HIGH>;
				reg = <0xb124000 0x1000>;
				status = "disabled";
			};

			frame@b125000 {
				frame-number = <3>;
				interrupts = <GIC_SPI 11 IRQ_TYPE_LEVEL_HIGH>;
				reg = <0xb125000 0x1000>;
				status = "disabled";
			};

			frame@b126000 {
				frame-number = <4>;
				interrupts = <GIC_SPI 12 IRQ_TYPE_LEVEL_HIGH>;
				reg = <0xb126000 0x1000>;
				status = "disabled";
			};

			frame@b127000 {
				frame-number = <5>;
				interrupts = <GIC_SPI 13 IRQ_TYPE_LEVEL_HIGH>;
				reg = <0xb127000 0x1000>;
				status = "disabled";
			};

			frame@b128000 {
				frame-number = <6>;
				interrupts = <GIC_SPI 14 IRQ_TYPE_LEVEL_HIGH>;
				reg = <0xb128000 0x1000>;
				status = "disabled";
			};
		};

		qmp_tmel: qmp-tmel@32090000 {
			compatible = "qti,tmel-qmp-mbox";
			reg = <0x32090000 0x20>,
			      <0x32091000 0x20>;
			reg-names = "mcore", "ucore";

			interrupts = <GIC_SPI 73 IRQ_TYPE_EDGE_RISING>;
			max_pkt_size = <0x18>;

			mboxes = <&apcs_glb 20>;
			qti,early-boot;
			#mbox-cells = <1>;
			status = "disabled";
		};

		tmelcom: qcom,tmelcom-qmp-client {
			compatible = "qcom,tmelcom-qmp-client";
			mboxes = <&qmp_tmel 0>;
			status = "disabled";
		};

		nsscc: clock-controller@39b00000 {
			compatible = "qcom,ipq5210-nsscc";
			reg = <0x39b00000 0x100000>;
			clocks = <&xo>,
				 <&cmn_pll IPQ5210_NSS_CLK>,
				 <&cmn_pll IPQ5210_PPE_CLK>,
				 <&gcc_gpll0_out_aux>,
				 <&ess_uniphy 0>,
				 <&ess_uniphy 1>,
				 <&ess_uniphy 2>,
				 <&ess_uniphy 3>,
				 <&ess_uniphy 4>,
				 <&ess_uniphy 5>,
				 <&cmn_pll IPQ5210_EPHY_RAW_CLK>,
				 <&cmn_pll IPQ5210_EPHY_RAW_CLK>;
			clock-names = "xo",
				      "nss",
				      "ppe",
				      "gpll0_out",
				      "uniphy0_rx",
				      "uniphy0_tx",
				      "uniphy1_rx",
				      "uniphy1_tx",
				      "uniphy2_rx",
				      "uniphy2_tx",
				      "ephy_rx",
				      "ephy_tx";
			#clock-cells = <1>;
			#reset-cells = <1>;
			#interconnect-cells = <1>;
			assigned-clocks = <&nsscc NSS_CC_EPHY_RX_CLK_SRC>,
					  <&nsscc NSS_CC_EPHY_TX_CLK_SRC>;
			assigned-clock-parents = <&nsscc NSS_CC_PORT4_RX_DIV_CLK_SRC>,
						 <&nsscc NSS_CC_PORT4_TX_DIV_CLK_SRC>;
		};

		eip: eip196@39800000 {
			compatible = "qcom,eip";
			reg-names = "eip_pbase";
			reg = <0x39800000 0x7ffff>;
			reg_offset = <0x80000>;
			ranges;
			clocks = <&nsscc NSS_CC_EIP_CLK>,
				<&nsscc NSS_CC_NSSNOC_EIP_CLK>;
			clock-names = "eip_clk", "eip_nocclk";
			clock-frequency = /bits/ 64 <375000000 375000000>;
			status = "ok";
			interrupts = <GIC_SPI 212 IRQ_TYPE_LEVEL_HIGH>,
				     <GIC_SPI 213 IRQ_TYPE_LEVEL_HIGH>,
				     <GIC_SPI 214 IRQ_TYPE_LEVEL_HIGH>,
				     <GIC_SPI 215 IRQ_TYPE_LEVEL_HIGH>;

			dma0 {
				tx_cpu = /bits/ 8 <0>;
				rx_cpu = /bits/ 8 <0>;
				ring-name = "lookaside";
				ring-id = /bits/ 8 <0>;
			};

			dma1 {
				tx_cpu = /bits/ 8 <1>;
				rx_cpu = /bits/ 8 <1>;
				ring-name = "lookaside";
				ring-id = /bits/ 8 <1>;
			};

			dma2 {
				tx_cpu = /bits/ 8 <2>;
				rx_cpu = /bits/ 8 <2>;
				ring-name = "lookaside";
				ring-id = /bits/ 8 <2>;
			};

			dma3 {
				tx_cpu = /bits/ 8 <3>;
				rx_cpu = /bits/ 8 <3>;
				ring-name = "lookaside";
				ring-id = /bits/ 8 <3>;
			};
		};

		eip_crypto: eip_crypto {
			compatible = "qcom,eip_crypto";
			status = "ok";
		};

		mdio@90000 {
			compatible = "qcom,qca-mdio", "qcom,ipq5210-mdio";
			pinctrl-0 = <&mdio_pins>;
			pinctrl-names = "default";
			reg = <0x90000 0x64>;
			clocks = <&gcc GCC_MDIO_AHB_CLK>;
			clock-names = "gcc_mdio_ahb_clk";
			#address-cells = <1>;
			#size-cells = <0>;
			status = "disabled";
		};

		ess_uniphy: ess-uniphy@7a00000 {
			compatible = "qcom,ess-uniphy";
			reg = <0x7a00000 0x30000>;
			uniphy_access_mode = "local bus";
			#clock-cells = <1>;
		};

		ess_instance: ess-instance {
			compatible = "qcom,ess-instance";
			num_devices = <0x1>;

			ess_switch: ess-switch@3a000000 {
				compatible = "qcom,ess-switch-ipq52xx";
				reg = <0x3a000000 0x1000000>;
				switch_access_mode = "local bus";
				switch_cpu_bmp = <0x1>;  /* cpu port bitmap */
				switch_inner_bmp = <0x80>; /*inner port bitmap*/
				bm_tick_mode = <0>; /* bm tick mode */
				tm_tick_mode = <0>; /* tm tick mode */
				clocks = <&gcc GCC_CMN_12GPLL_AHB_CLK>,
					<&gcc GCC_CMN_12GPLL_SYS_CLK>,
					<&gcc GCC_UNIPHY0_AHB_CLK>,
					<&gcc GCC_UNIPHY0_SYS_CLK>,
					<&gcc GCC_UNIPHY1_AHB_CLK>,
					<&gcc GCC_UNIPHY1_SYS_CLK>,
					<&gcc GCC_UNIPHY2_AHB_CLK>,
					<&gcc GCC_UNIPHY2_SYS_CLK>,
					<&gcc GCC_NSSNOC_NSSCC_CLK>,
					<&gcc GCC_NSSCC_CLK>,
					<&gcc GCC_NSSNOC_SNOC_1_CLK>,
					<&gcc GCC_NSSNOC_SNOC_CLK>,
					<&nsscc NSS_CC_PORT1_MAC_CLK>,
					<&nsscc NSS_CC_PORT2_MAC_CLK>,
					<&nsscc NSS_CC_PORT3_MAC_CLK>,
					<&nsscc NSS_CC_PORT4_MAC_CLK>,
					<&nsscc NSS_CC_PORT5_MAC_CLK>,
					<&nsscc NSS_CC_PORT6_MAC_CLK>,
					<&nsscc NSS_CC_PPE_SWITCH_CLK>,
					<&nsscc NSS_CC_PPE_SWITCH_CFG_CLK>,
					<&nsscc NSS_CC_NSSNOC_PPE_CLK>,
					<&nsscc NSS_CC_NSSNOC_PPE_CFG_CLK>,
					<&nsscc NSS_CC_PPE_EDMA_CLK>,
					<&nsscc NSS_CC_PPE_EDMA_CFG_CLK>,
					<&nsscc NSS_CC_PPE_SWITCH_IPE_CLK>,
					<&nsscc NSS_CC_PPE_SWITCH_BTQ_CLK>,
					<&nsscc NSS_CC_PORT1_RX_CLK>,
					<&nsscc NSS_CC_PORT1_TX_CLK>,
					<&nsscc NSS_CC_PORT2_RX_CLK>,
					<&nsscc NSS_CC_PORT2_TX_CLK>,
					<&nsscc NSS_CC_PORT3_RX_CLK>,
					<&nsscc NSS_CC_PORT3_TX_CLK>,
					<&nsscc NSS_CC_PORT4_RX_CLK>,
					<&nsscc NSS_CC_PORT4_TX_CLK>,
					<&nsscc NSS_CC_PORT5_RX_CLK>,
					<&nsscc NSS_CC_PORT5_TX_CLK>,
					<&nsscc NSS_CC_PORT6_RX_CLK>,
					<&nsscc NSS_CC_PORT6_TX_CLK>,
					<&nsscc NSS_CC_UNIPHY_PORT1_RX_CLK>,
					<&nsscc NSS_CC_UNIPHY_PORT1_TX_CLK>,
					<&nsscc NSS_CC_UNIPHY_PORT2_RX_CLK>,
					<&nsscc NSS_CC_UNIPHY_PORT2_TX_CLK>,
					<&nsscc NSS_CC_UNIPHY_PORT3_RX_CLK>,
					<&nsscc NSS_CC_UNIPHY_PORT3_TX_CLK>,
					<&nsscc NSS_CC_UNIPHY_PORT4_RX_CLK>,
					<&nsscc NSS_CC_UNIPHY_PORT4_TX_CLK>,
					<&nsscc NSS_CC_UNIPHY_PORT5_RX_CLK>,
					<&nsscc NSS_CC_UNIPHY_PORT5_TX_CLK>,
					<&nsscc NSS_CC_UNIPHY_PORT6_RX_CLK>,
					<&nsscc NSS_CC_UNIPHY_PORT6_TX_CLK>,
					<&cmn_pll IPQ5210_EPHY_RAW_CLK>,
					<&cmn_pll IPQ5210_EPHY_RAW_CLK>,
					<&nsscc NSS_CC_PORT4_RX_CLK_SRC>,
					<&nsscc NSS_CC_PORT4_TX_CLK_SRC>,
					<&nsscc NSS_CC_PORT5_RX_CLK_SRC>,
					<&nsscc NSS_CC_PORT5_TX_CLK_SRC>,
					<&nsscc NSS_CC_UNIPHY_PORT1_RX_DIV4_CLK>,
					<&nsscc NSS_CC_UNIPHY_PORT1_TX_DIV4_CLK>,
					<&nsscc NSS_CC_UNIPHY_PORT2_RX_DIV4_CLK>,
					<&nsscc NSS_CC_UNIPHY_PORT2_TX_DIV4_CLK>,
					<&nsscc NSS_CC_UNIPHY_PORT3_RX_DIV4_CLK>,
					<&nsscc NSS_CC_UNIPHY_PORT3_TX_DIV4_CLK>,
					<&nsscc NSS_CC_UNIPHY_PORT4_RX_DIV4_CLK>,
					<&nsscc NSS_CC_UNIPHY_PORT4_TX_DIV4_CLK>;
				clock-names = "cmn_ahb_clk",
					"cmn_sys_clk",
					"uniphy0_ahb_clk",
					"uniphy0_sys_clk",
					"uniphy1_ahb_clk",
					"uniphy1_sys_clk",
					"uniphy2_ahb_clk",
					"uniphy2_sys_clk",
					"gcc_nssnoc_nsscc_clk",
					"gcc_nsscc_clk",
					"gcc_nssnoc_snoc_1_clk",
					"gcc_nssnoc_snoc_clk",
					"port1_mac_clk",
					"port2_mac_clk",
					"port3_mac_clk",
					"port4_mac_clk",
					"port5_mac_clk",
					"port6_mac_clk",
					"nss_ppe_clk",
					"nss_ppe_cfg_clk",
					"nssnoc_ppe_clk",
					"nssnoc_ppe_cfg_clk",
					"nss_edma_clk",
					"nss_edma_cfg_clk",
					"nss_ppe_ipe_clk",
					"nss_ppe_btq_clk",
					"nss_port1_rx_clk",
					"nss_port1_tx_clk",
					"nss_port2_rx_clk",
					"nss_port2_tx_clk",
					"nss_port3_rx_clk",
					"nss_port3_tx_clk",
					"nss_port4_rx_clk",
					"nss_port4_tx_clk",
					"nss_port5_rx_clk",
					"nss_port5_tx_clk",
					"nss_port6_rx_clk",
					"nss_port6_tx_clk",
					"uniphy0_port1_rx_clk",
					"uniphy0_port1_tx_clk",
					"uniphy0_port2_rx_clk",
					"uniphy0_port2_tx_clk",
					"uniphy0_port3_rx_clk",
					"uniphy0_port3_tx_clk",
					"uniphy0_port4_rx_clk",
					"uniphy0_port4_tx_clk",
					"uniphy1_port5_rx_clk",
					"uniphy1_port5_tx_clk",
					"uniphy2_port6_rx_clk",
					"uniphy2_port6_tx_clk",
					"ephy_rx_clk_src_parent",
					"ephy_tx_clk_src_parent",
					"nss_port4_rx_clk_src",
					"nss_port4_tx_clk_src",
					"nss_port5_rx_clk_src",
					"nss_port5_tx_clk_src",
					"uniphy_port1_rx_div4_clk",
					"uniphy_port1_tx_div4_clk",
					"uniphy_port2_rx_div4_clk",
					"uniphy_port2_tx_div4_clk",
					"uniphy_port3_rx_div4_clk",
					"uniphy_port3_tx_div4_clk",
					"uniphy_port4_rx_div4_clk",
					"uniphy_port4_tx_div4_clk";
				resets = <&nsscc NSS_CC_PPE_BCR>,
					<&gcc GCC_UNIPHY0_BCR>,
					<&gcc GCC_UNIPHY1_BCR>,
					<&gcc GCC_UNIPHY2_BCR>,
					<&gcc GCC_UNIPHY0_AHB_ARES>,
					<&gcc GCC_UNIPHY1_AHB_ARES>,
					<&gcc GCC_UNIPHY2_AHB_ARES>,
					<&gcc GCC_UNIPHY0_SYS_ARES>,
					<&gcc GCC_UNIPHY1_SYS_ARES>,
					<&gcc GCC_UNIPHY2_SYS_ARES>,
					<&gcc GCC_UNIPHY0_XPCS_ARES>,
					<&gcc GCC_UNIPHY1_XPCS_ARES>,
					<&gcc GCC_UNIPHY2_XPCS_ARES>,
					<&nsscc NSS_CC_UNIPHY_PORT1_RX_CLK_ARES>,
					<&nsscc NSS_CC_UNIPHY_PORT1_TX_CLK_ARES>,
					<&nsscc NSS_CC_UNIPHY_PORT2_RX_CLK_ARES>,
					<&nsscc NSS_CC_UNIPHY_PORT2_TX_CLK_ARES>,
					<&nsscc NSS_CC_UNIPHY_PORT3_RX_CLK_ARES>,
					<&nsscc NSS_CC_UNIPHY_PORT3_TX_CLK_ARES>,
					<&nsscc NSS_CC_UNIPHY_PORT4_RX_CLK_ARES>,
					<&nsscc NSS_CC_UNIPHY_PORT4_TX_CLK_ARES>,
					<&nsscc NSS_CC_UNIPHY_PORT5_RX_CLK_ARES>,
					<&nsscc NSS_CC_UNIPHY_PORT5_TX_CLK_ARES>,
					<&nsscc NSS_CC_UNIPHY_PORT6_RX_CLK_ARES>,
					<&nsscc NSS_CC_UNIPHY_PORT6_TX_CLK_ARES>,
					<&nsscc NSS_CC_PORT1_RX_CLK_ARES>,
					<&nsscc NSS_CC_PORT1_TX_CLK_ARES>,
					<&nsscc NSS_CC_PORT2_RX_CLK_ARES>,
					<&nsscc NSS_CC_PORT2_TX_CLK_ARES>,
					<&nsscc NSS_CC_PORT3_RX_CLK_ARES>,
					<&nsscc NSS_CC_PORT3_TX_CLK_ARES>,
					<&nsscc NSS_CC_PORT4_RX_CLK_ARES>,
					<&nsscc NSS_CC_PORT4_TX_CLK_ARES>,
					<&nsscc NSS_CC_PORT5_RX_CLK_ARES>,
					<&nsscc NSS_CC_PORT5_TX_CLK_ARES>,
					<&nsscc NSS_CC_PORT6_RX_CLK_ARES>,
					<&nsscc NSS_CC_PORT6_TX_CLK_ARES>,
					<&nsscc NSS_CC_PORT1_MAC_CLK_ARES>,
					<&nsscc NSS_CC_PORT2_MAC_CLK_ARES>,
					<&nsscc NSS_CC_PORT3_MAC_CLK_ARES>,
					<&nsscc NSS_CC_PORT4_MAC_CLK_ARES>,
					<&nsscc NSS_CC_PORT5_MAC_CLK_ARES>,
					<&nsscc NSS_CC_PORT6_MAC_CLK_ARES>;
				reset-names = "ppe_rst",
					"uniphy0_soft_rst",
					"uniphy1_soft_rst",
					"uniphy2_soft_rst",
					"uniphy0_ahb_rst",
					"uniphy1_ahb_rst",
					"uniphy2_ahb_rst",
					"uniphy0_sys_rst",
					"uniphy1_sys_rst",
					"uniphy2_sys_rst",
					"uniphy0_xpcs_rst",
					"uniphy1_xpcs_rst",
					"uniphy2_xpcs_rst",
					"uniphy_port1_rx_rst",
					"uniphy_port1_tx_rst",
					"uniphy_port2_rx_rst",
					"uniphy_port2_tx_rst",
					"uniphy_port3_rx_rst",
					"uniphy_port3_tx_rst",
					"uniphy_port4_rx_rst",
					"uniphy_port4_tx_rst",
					"uniphy_port5_rx_rst",
					"uniphy_port5_tx_rst",
					"uniphy_port6_rx_rst",
					"uniphy_port6_tx_rst",
					"nss_port1_rx_rst",
					"nss_port1_tx_rst",
					"nss_port2_rx_rst",
					"nss_port2_tx_rst",
					"nss_port3_rx_rst",
					"nss_port3_tx_rst",
					"nss_port4_rx_rst",
					"nss_port4_tx_rst",
					"nss_port5_rx_rst",
					"nss_port5_tx_rst",
					"nss_port6_rx_rst",
					"nss_port6_tx_rst",
					"nss_port1_mac_rst",
					"nss_port2_mac_rst",
					"nss_port3_mac_rst",
					"nss_port4_mac_rst",
					"nss_port5_mac_rst",
					"nss_port6_mac_rst";

				port_scheduler_resource {
					port@0 {
						port_id = <0>;
						ucast_queue = <170 254>;
						mcast_queue = <256 271>;
						l0sp = <44 56>;
						l0cdrr = <170 255>;
						l0edrr = <170 255>;
						l1cdrr = <44 56>;
						l1edrr = <44 56>;
					};
					port@1 {
						port_id = <1>;
						ucast_queue = <0 7>;
						mcast_queue = <272 275>;
						l0sp = <0 1>;
						l0cdrr = <0 7>;
						l0edrr = <0 7>;
						l1cdrr = <0 1>;
						l1edrr = <0 1>;
					};
					port@2 {
						port_id = <2>;
						ucast_queue = <8 15>;
						mcast_queue = <276 279>;
						l0sp = <2 3>;
						l0cdrr = <8 15>;
						l0edrr = <8 15>;
						l1cdrr = <2 3>;
						l1edrr = <2 3>;
					};
					port@3 {
						port_id = <3>;
						ucast_queue = <16 23>;
						mcast_queue = <280 283>;
						l0sp = <4 5>;
						l0cdrr = <16 23>;
						l0edrr = <16 23>;
						l1cdrr = <4 5>;
						l1edrr = <4 5>;
					};
					port@4 {
						port_id = <4>;
						ucast_queue = <24 31>;
						mcast_queue = <284 287>;
						l0sp = <6 7>;
						l0cdrr = <24 31>;
						l0edrr = <24 31>;
						l1cdrr = <6 7>;
						l1edrr = <6 7>;
					};
					port@5 {
						port_id = <5>;
						ucast_queue = <32 39>;
						mcast_queue = <288 291>;
						l0sp = <8 9>;
						l0cdrr = <32 39>;
						l0edrr = <32 39>;
						l1cdrr = <8 9>;
						l1edrr = <8 9>;
					};
					port@6 {
						port_id = <6>;
						ucast_queue = <40 159>;
						mcast_queue = <292 295>;
						l0sp = <10 41>;
						l0cdrr = <40 159>;
						l0edrr = <40 159>;
						l1cdrr = <10 41>;
						l1edrr = <10 41>;
					};
					port@7 {
						port_id = <7>;
						ucast_queue = <160 169>;
						mcast_queue = <296 299>;
						l0sp = <42 43>;
						l0cdrr = <160 169>;
						l0edrr = <160 169>;
						l1cdrr = <42 43>;
						l1edrr = <42 43>;
					};
					reserved {
						ucast_queue = <255 255>;
						mcast_queue = <0 0>;
						l0sp = <57 63>;
						l0cdrr = <0 0>;
						l0edrr = <0 0>;
						l1cdrr = <57 63>;
						l1edrr = <57 63>;
					};
				};

				port_scheduler_config {
					port@0 {
						port_id = <0>;
						l1scheduler {
							group@0 {
								/* L0 SP */
								sp = <44>;
								sp_loop_pri = <13>;
								sp_max_pri = <1>;
								/* cpri cdrr epri edrr */
								cfg = <0 44 0 44>;
							};
						};
						l0scheduler {
							group@0 {
								/* 8 x (4 cores + 2 VP) */
								ucast_queue = <170>;
								ucast_loop_pri = <48>;
								ucast_max_pri = <8>;
								/* multicast queue */
								mcast_queue = <256>;
								mcast_loop_pri = <8>;
								/* sp cpri cdrr epri edrr */
								cfg = <44 0 170 0 170>;
							};
							group@1 {
								/* 4 GRO + 1x4 SMD */
								ucast_queue = <218>;
								ucast_loop_pri = <8>;
								ucast_max_pri = <4>;
								mcast_queue = <264>;
								mcast_loop_pri = <8>;
								cfg = <50 0 218 0 218>;
							};
							group@2 {
								/* DS */
								ucast_queue = <226>;
								ucast_loop_pri = <8>;
								cfg = <52 0 226 0 226>;
							};

							group@3 {
								/* SMD DS */
								ucast_queue = <234>;
								ucast_loop_pri = <4>;
								cfg = <53 0 234 0 234>;
							};

							group@4 {
								/* Ingress SRAM for DDRQ */
								ucast_queue = <238>;
								ucast_loop_pri = <17>;
								ucast_max_pri = <8>;
								cfg = <54 0 238 0 238>;
							};
						};
					};
					port@1 {
						port_id = <1>;
						l1scheduler {
							group@0 {
								sp = <0>;
								cfg = <0 0 0 0>;
							};
						};
						l0scheduler {
							group@0 {
								ucast_queue = <0>;
								ucast_loop_pri = <8>;
								mcast_queue = <272>;
								mcast_loop_pri = <4>;
								cfg = <0 0 0 0 0>;
							};
						};
					};
					port@2 {
						port_id = <2>;
						l1scheduler {
							group@0 {
								sp = <2>;
								cfg = <0 2 0 2>;
							};
						};
						l0scheduler {
							group@0 {
								ucast_queue = <8>;
								ucast_loop_pri = <8>;
								mcast_queue = <276>;
								mcast_loop_pri = <4>;
								cfg = <2 0 8 0 8>;
							};
						};
					};
					port@3 {
						port_id = <3>;
						l1scheduler {
							group@0 {
								sp = <4>;
								cfg = <0 4 0 4>;
							};
						};
						l0scheduler {
							group@0 {
								ucast_queue = <16>;
								ucast_loop_pri = <8>;
								mcast_queue = <280>;
								mcast_loop_pri = <4>;
								cfg = <4 0 16 0 16>;
							};
						};
					};
					port@4 {
						port_id = <4>;
						l1scheduler {
							group@0 {
								sp = <6>;
								cfg = <0 6 0 6>;
							};
						};
						l0scheduler {
							group@0 {
								ucast_queue = <24>;
								ucast_loop_pri = <8>;
								mcast_queue = <284>;
								mcast_loop_pri = <4>;
								cfg = <6 0 24 0 24>;
							};
						};
					};
					port@5 {
						port_id = <5>;
						l1scheduler {
							group@0 {
								sp = <8>;
								cfg = <0 8 0 8>;
							};
						};
						l0scheduler {
							group@0 {
								ucast_queue = <32>;
								ucast_loop_pri = <8>;
								mcast_queue = <288>;
								mcast_loop_pri = <4>;
								cfg = <8 0 32 0 32>;
							};
						};
					};

					port@6 {
						port_id = <6>;
						l1scheduler {
							group@0 {
								sp = <10>;
								sp_loop_pri = <15>;
								sp_max_pri = <1>;
								cfg = <6 0 10 0 10>;
							};
						};
						l0scheduler {
							group@0 {
								ucast_queue = <40>;
								ucast_loop_pri = <120>;
								ucast_max_pri = <8>;
								mcast_queue = <292>;
								mcast_loop_pri = <4>;
								cfg = <10 0 40 0 40>;
							};
						};
					};

					port@7 {
						port_id = <7>;
						l1scheduler {
							group@0 {
								sp = <42>;
								sp_loop_pri = <2>;
								sp_max_pri = <1>;
								cfg = <0 42 0 42>;
							};
						};
						l0scheduler {
							group@0 {
								ucast_queue = <160>;
								ucast_loop_pri = <10>;
								ucast_max_pri = <8>;
								mcast_queue = <296>;
								mcast_loop_pri = <4>;
								cfg = <42 0 160 0 160>;
							};
						};
					};
				};
			};
		};

		/* EDMA host driver configuration */
		edma@3ad00000 {
			compatible = "qcom,edma";
			reg = <0x3ad00000 0x1C5000>;
			reg-names = "edma-reg-base";
			resets = <&nsscc NSS_CC_PPE_EDMA_CLK_ARES>,
			       <&nsscc NSS_CC_PPE_EDMA_CFG_CLK_ARES>;
			reset-names = "edma_rst",
				"edma_cfg_rst";
			qcom,rxdesc-ring-max = <24>;
			qcom,rxfill-ring-max = <20>;
			qcom,txdesc-ring-max = <24>;
			qcom,txcomp-ring-max = <20>;
			qcom,rx-page-mode = <0>;
			qcom,tx-map-priority-level = <1>;
			qcom,rx-map-priority-level = <1>;
			qcom,txdesc-fc-grp-map = <1 2 3 4 5 6>;
			qcom,vp-id = <8>;
			interrupts = <0 332 4>, <0 333 4>, <0 334 4>, <0 335 4>,
				   <0 336 4>, <0 337 4>, <0 338 4>, <0 339 4>,
				   <0 340 4>, <0 341 4>, <0 342 4>, <0 343 4>,
				   <0 344 4>, <0 345 4>, <0 346 4>, <0 347 4>,
				   <0 348 4>, <0 349 4>, <0 350 4>, <0 351 4>, /* TX Complete ring IRQ info (0 - 19) */

				   <0 288 4>, <0 289 4>, <0 290 4>, <0 291 4>,
				   <0 292 4>, <0 293 4>, <0 294 4>, <0 295 4>,
				   <0 296 4>, <0 297 4>, <0 298 4>, <0 299 4>,
				   <0 300 4>, <0 301 4>, <0 302 4>, <0 303 4>,
				   <0 304 4>, <0 305 4>, <0 306 4>, <0 307 4>,
				   <0 308 4>, <0 309 4>, <0 310 4>, <0 311 4>, /* RX desc ring IRQ info (0 - 23) */

				   <0 312 4>, <0 313 4>, <0 314 4>, <0 315 4>,
				   <0 316 4>, <0 317 4>, <0 318 4>, <0 319 4>,
				   <0 320 4>, <0 321 4>, <0 322 4>, <0 323 4>,
				   <0 324 4>, <0 325 4>, <0 326 4>, <0 327 4>,
				   <0 328 4>, <0 329 4>, <0 330 4>, <0 331 4>, /* RX fill ring IRQ info (0 - 19) */

				   <0 352 4>;					/* Misc interrupt */
			interrupt-names = "txcmpl_0", "txcmpl_1", "txcmpl_2", "txcmpl_3",
				   "txcmpl_4", "txcmpl_5", "txcmpl_6", "txcmpl_7",
				   "txcmpl_8", "txcmpl_9", "txcmpl_10", "txcmpl_11",
				   "txcmpl_12", "txcmpl_13", "txcmpl_14", "txcmpl_15",
				   "txcmpl_16", "txcmpl_17", "txcmpl_18", "txcmpl_19",

				   "rxdesc_0", "rxdesc_1", "rxdesc_2", "rxdesc_3",
				   "rxdesc_4", "rxdesc_5", "rxdesc_6", "rxdesc_7",
				   "rxdesc_8", "rxdesc_9", "rxdesc_10", "rxdesc_11",
				   "rxdesc_12", "rxdesc_13", "rxdesc_14", "rxdesc_15",
				   "rxdesc_16", "rxdesc_17", "rxdesc_18", "rxdesc_19",
				   "rxdesc_20", "rxdesc_21", "rxdesc_22", "rxdesc_23",

				   "rxfill_0", "rxfill_1", "rxfill_2", "rxfill_3",
				   "rxfill_4", "rxfill_5", "rxfill_6", "rxfill_7",
				   "rxfill_8", "rxfill_9", "rxfill_10", "rxfill_11",
				   "rxfill_12", "rxfill_13", "rxfill_14", "rxfill_15",
				   "rxfill_16", "rxfill_17", "rxfill_18", "rxfill_19",

				   "misc_err";
			clocks = <&nsscc NSS_CC_NSS_CSR_CLK>,
				<&nsscc NSS_CC_NSSNOC_NSS_CSR_CLK>,
				<&nsscc NSS_CC_PPE_EDMA_CLK>,
				<&gcc GCC_NSSNOC_ATB_CLK>,
				<&gcc GCC_NSS_TS_CLK>,
				<&gcc GCC_NSSNOC_QOSGEN_REF_CLK>,
				<&gcc GCC_NSSNOC_TIMEOUT_REF_CLK>,
				<&gcc GCC_NSSNOC_SNOC_CLK>,
				<&gcc GCC_NSSCFG_CLK>,
				<&gcc GCC_NSSNOC_NSSCC_CLK>,
				<&gcc GCC_NSSCC_CLK>,
				<&gcc GCC_NSSNOC_XO_DCD_CLK>,
				<&gcc GCC_NSSNOC_SNOC_1_CLK>,
				<&gcc GCC_NSSNOC_PCNOC_1_CLK>,
				<&gcc GCC_NSSNOC_MEMNOC_CLK>,
				<&gcc GCC_NSSNOC_MEMNOC_1_CLK>;
			clock-names = "nss-csr-clk", "nss-nssnoc-csr-clk",
				"nss-edma-clk", "nss-nssnoc-atb-clk", "nss-ts-clk",
				"nss-nssnoc-qosgen-ref-clk", "nss-nssnoc-timeout-ref-clk",
				"nss-nssnoc-snoc-clk", "nss-nsscfg-clk", "nss-nssnoc-nsscc-clk",
				"nss-nsscc-clk", "nss-nssnoc-xo-dcd-clk", "nss-nssnoc-snoc-1-clk",
				"nss-nssnoc-pcnoc-1-clk", "nss-nssnoc-memnoc-clk",
				"nss-nssnoc-mem-noc-1-clk";
		};

		nss-ppe {
			compatible = "qcom,nss-ppe";
		};
	};

	firmware {
		scm {
			compatible = "qcom,scm-ipq5210", "qcom,scm";
			qcom,dload-mode = <&tcsr 0x25100>;
		};

		optee {
			compatible = "linaro,optee-tz";
			method = "smc";
		};
	};

	tmel-log {
		compatible = "qcom,tmel-log-ipq5210";
	};

	qcom,test@0 {
		compatible = "qcom,testmhi";
	};

	psci {
		compatible = "arm,psci-1.0";
		method = "smc";
	};

	qti,tfa-optee-log {
		compatible = "qti,tfa-optee-log";
		interrupts = <GIC_SPI 267 IRQ_TYPE_EDGE_RISING>;
		tfa-diag-info =<&tfa_diag_buf>;
		optee-diag-info =<&optee_diag_buf>;
	};

	ctx-save {
		compatible = "qti,ctxt-save-ipq5210";
		memory-region = <&minidump_mem>;
		qcom,imem = <&imem>;
		minidump-level = <2>;
	};

	pmu {
		compatible = "arm,cortex-a53-pmu";
		interrupts = <GIC_PPI 7 (GIC_CPU_MASK_SIMPLE(4) | IRQ_TYPE_LEVEL_HIGH)>;
	};

	pmu-v7 {
		compatible = "arm,cortex-a7-pmu";
		interrupts = <GIC_PPI 7 (GIC_CPU_MASK_SIMPLE(4) | IRQ_TYPE_LEVEL_HIGH)>;
	};

	thermal_zones: thermal-zones {
		ethphy-thermal {
			polling-delay-passive = <0>;
			polling-delay = <0>;
			thermal-sensors = <&tsens 11>;

			trips {
				ethphy-critical {
					temperature = <120000>;
					hysteresis = <9000>;
					type = "critical";
				};
			};
		};

		pon-uniphy-thermal {
			polling-delay-passive = <0>;
			polling-delay = <0>;
			thermal-sensors = <&tsens 12>;

			trips {
				pon-uniphy-critical {
					temperature = <120000>;
					hysteresis = <9000>;
					type = "critical";
				};
			};
		};

		nss-top-thermal {
			polling-delay-passive = <0>;
			polling-delay = <0>;
			thermal-sensors = <&tsens 13>;

			trips {
				nss-top-critical {
					temperature = <120000>;
					hysteresis = <9000>;
					type = "critical";
				};
			};
		};

		a53ss-cm-dist-ts-0-thermal {
			polling-delay-passive = <0>;
			polling-delay = <0>;
			thermal-sensors = <&tsens 14>;

			trips {
				a53ss-cm-dist-ts-0-critical {
					temperature = <120000>;
					hysteresis = <9000>;
					type = "critical";
				};
			};
		};

		a53ss-cm-dist-ts-1-thermal {
			polling-delay-passive = <0>;
			polling-delay = <0>;
			thermal-sensors = <&tsens 15>;

			trips {
				a53ss-cm-dist-ts-1-critical {
					temperature = <120000>;
					hysteresis = <9000>;
					type = "critical";
				};
			};
		};
	};
};
